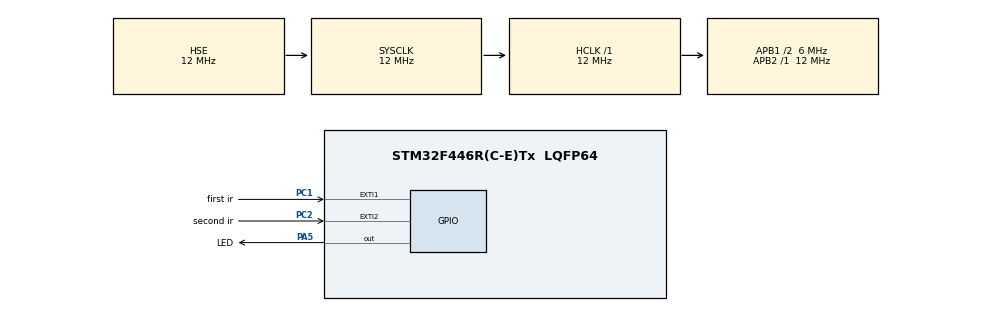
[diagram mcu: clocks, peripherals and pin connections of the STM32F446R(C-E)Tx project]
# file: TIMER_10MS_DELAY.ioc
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Mcu.Family=STM32F4
Mcu.Name=STM32F446R(C-E)Tx
Mcu.Package=LQFP64
NVIC.EXTI1_IRQn=true\:0\:0\:false\:false\:true\:true\:true
NVIC.EXTI2_IRQn=true\:0\:0\:false\:false\:true\:true\:true
NVIC.PriorityGroup=NVIC_PRIORITYGROUP_4
NVIC.TIM6_DAC_IRQn=true\:0\:0\:false\:false\:true\:true\:true
PA5.GPIO_Label=LED
PA5.Signal=GPIO_Output
PC1.GPIO_Label=first ir
PC1.GPIO_ModeDefaultEXTI=GPIO_MODE_IT_RISING
PC1.GPIO_PuPd=GPIO_PULLDOWN
PC1.Signal=GPXTI1
PC2.GPIO_Label=second ir
PC2.GPIO_ModeDefaultEXTI=GPIO_MODE_IT_RISING
PC2.GPIO_PuPd=GPIO_PULLDOWN
PC2.Signal=GPXTI2
PH0-OSC_IN.Mode=HSE-External-Oscillator
PH0-OSC_IN.Signal=RCC_OSC_IN
PH1-OSC_OUT.Mode=HSE-External-Oscillator
PH1-OSC_OUT.Signal=RCC_OSC_OUT
ProjectManager.HeapSize=0x200
ProjectManager.StackSize=0x400
ProjectManager.TargetToolchain=SW4STM32
RCC.AHBFreq_Value=12000000
RCC.APB1CLKDivider=RCC_HCLK_DIV2
RCC.APB1Freq_Value=6000000
RCC.APB1TimFreq_Value=12000000
RCC.APB2Freq_Value=12000000
RCC.APB2TimFreq_Value=12000000
RCC.CortexFreq_Value=12000000
RCC.HCLKFreq_Value=12000000
RCC.HSE_VALUE=12000000
RCC.PLLM=4
RCC.PLLN=50
RCC.PLLSourceVirtual=RCC_PLLSOURCE_HSE
RCC.SYSCLKFreq_VALUE=12000000
RCC.SYSCLKSource=RCC_SYSCLKSOURCE_HSE
RCC.USBFreq_Value=75000000
RCC.VCOOutputFreq_Value=150000000
TIM6.AutoReloadPreload=TIM_AUTORELOAD_PRELOAD_ENABLE
TIM6.Period=120
TIM6.Prescaler=1000
VP_TIM6_VS_ClockSourceINT.Mode=Enable_Timer
board=custom

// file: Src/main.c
/* USER CODE BEGIN Header */
/**
  ******************************************************************************
  * @file           : main.c
  * @brief          : Main program body
  ******************************************************************************
  * @attention
  *
  * <h2><center>&copy; Copyright (c) 2021 STMicroelectronics.
  * All rights reserved.</center></h2>
  *
  * This software component is licensed by ST under BSD 3-Clause license,
  * the "License"; You may not use this file except in compliance with the
  * License. You may obtain a copy of the License at:
  *                        opensource.org/licenses/BSD-3-Clause
  *
  ******************************************************************************
  */
/* USER CODE END Header */

#include "main.h"

TIM_HandleTypeDef htim6;

/* USER CODE BEGIN PV */
float ticks=0.00;
double volume=0.00;
unsigned long overflow=0;
double flow=0.00;		   //for flow calculation flow=vol*60/sec
char flowres[20]={0};
char ticksres[20]={0};
unsigned int countervalue=0;

/* USER CODE END PV */

void SystemClock_Config(void);
static void MX_GPIO_Init(void);
static void MX_TIM6_Init(void);

int main(void)
{
  /* USER CODE BEGIN 1 */
  float id=1.82;   //DIAMETER=3.64 SO ID=DIA/2
  int height=47;
  double pie=3.14159265358; //pie value used for volume calculation

  volume=((pie*(id)*(id)*height)/1000)*60;

  /* USER CODE END 1 */

  /* MCU Configuration--------------------------------------------------------*/

  /* Reset of all peripherals, Initializes the Flash interface and the Systick. */
  HAL_Init();

  /* Configure the system clock */
  SystemClock_Config();

  /* Initialize all configured peripherals */
  MX_GPIO_Init();
  MX_TIM6_Init();
//  HAL_TIM_Base_Start_IT(&htim6);
  /* USER CODE BEGIN 2 */
  HAL_NVIC_DisableIRQ(EXTI2_IRQn); //disable second interrupt in our case it is ir2

  /* USER CODE END 2 */

  /* Infinite loop */
  while (1)
  {

  }
}

void SystemClock_Config(void)
{
  RCC_OscInitTypeDef RCC_OscInitStruct = {0};
  RCC_ClkInitTypeDef RCC_ClkInitStruct = {0};

  /** Configure the main internal regulator output voltage
  */
  __HAL_RCC_PWR_CLK_ENABLE();
  __HAL_PWR_VOLTAGESCALING_CONFIG(PWR_REGULATOR_VOLTAGE_SCALE3);
  /** Initializes the CPU, AHB and APB busses clocks
  */
  RCC_OscInitStruct.OscillatorType = RCC_OSCILLATORTYPE_HSE;
  RCC_OscInitStruct.HSEState = RCC_HSE_ON;
  RCC_OscInitStruct.PLL.PLLState = RCC_PLL_NONE;
  if (HAL_RCC_OscConfig(&RCC_OscInitStruct) != HAL_OK)
  {
    Error_Handler();
  }
  /** Initializes the CPU, AHB and APB busses clocks
  */
  RCC_ClkInitStruct.ClockType = RCC_CLOCKTYPE_HCLK|RCC_CLOCKTYPE_SYSCLK
                              |RCC_CLOCKTYPE_PCLK1|RCC_CLOCKTYPE_PCLK2;
  RCC_ClkInitStruct.SYSCLKSource = RCC_SYSCLKSOURCE_HSE;
  RCC_ClkInitStruct.AHBCLKDivider = RCC_SYSCLK_DIV1;
  RCC_ClkInitStruct.APB1CLKDivider = RCC_HCLK_DIV2;
  RCC_ClkInitStruct.APB2CLKDivider = RCC_HCLK_DIV1;

  if (HAL_RCC_ClockConfig(&RCC_ClkInitStruct, FLASH_LATENCY_0) != HAL_OK)
  {
    Error_Handler();
  }
}

static void MX_TIM6_Init(void)
{

  TIM_MasterConfigTypeDef sMasterConfig = {0};

  htim6.Instance = TIM6;
 // htim6.Init.Prescaler = 1000;      //USING 12MHZ CLOCK SPEED(can be set to one)
  htim6.Init.Prescaler = 1;
  htim6.Init.CounterMode = TIM_COUNTERMODE_UP;
 // htim6.Init.Period = 12000;    //1s delay
  htim6.Init.Period = 65536-1;
  htim6.Init.AutoReloadPreload = TIM_AUTORELOAD_PRELOAD_ENABLE;
  if (HAL_TIM_Base_Init(&htim6) != HAL_OK)
  {
    Error_Handler();
  }
  sMasterConfig.MasterOutputTrigger = TIM_TRGO_RESET;
  sMasterConfig.MasterSlaveMode = TIM_MASTERSLAVEMODE_DISABLE;
  if (HAL_TIMEx_MasterConfigSynchronization(&htim6, &sMasterConfig) != HAL_OK)
  {
    Error_Handler();
  }

}

static void MX_GPIO_Init(void)
{
  GPIO_InitTypeDef GPIO_InitStruct = {0};

  /* GPIO Ports Clock Enable */
  __HAL_RCC_GPIOH_CLK_ENABLE();
  __HAL_RCC_GPIOC_CLK_ENABLE();
  __HAL_RCC_GPIOA_CLK_ENABLE();

  /*Configure GPIO pin Output Level */
  HAL_GPIO_WritePin(LED_GPIO_Port, LED_Pin, GPIO_PIN_RESET);

  /*Configure GPIO pins : first_ir_Pin second_ir_Pin */
  GPIO_InitStruct.Pin = first_ir_Pin|second_ir_Pin;
  GPIO_InitStruct.Mode = GPIO_MODE_IT_RISING;
  GPIO_InitStruct.Pull = GPIO_PULLDOWN;
  HAL_GPIO_Init(GPIOC, &GPIO_InitStruct);

  /*Configure GPIO pin : LED_Pin */
  GPIO_InitStruct.Pin = LED_Pin;
  GPIO_InitStruct.Mode = GPIO_MODE_OUTPUT_PP;
  GPIO_InitStruct.Pull = GPIO_NOPULL;
  GPIO_InitStruct.Speed = GPIO_SPEED_FREQ_LOW;
  HAL_GPIO_Init(LED_GPIO_Port, &GPIO_InitStruct);

  /* EXTI interrupt init*/
  HAL_NVIC_SetPriority(EXTI1_IRQn, 0, 0);
  HAL_NVIC_EnableIRQ(EXTI1_IRQn);

  HAL_NVIC_SetPriority(EXTI2_IRQn, 0, 0);
  HAL_NVIC_EnableIRQ(EXTI2_IRQn);

}

void Error_Handler(void)
{
}

void HAL_GPIO_EXTI_Callback(uint16_t GPIO_Pin)
{
	if(GPIO_Pin == GPIO_PIN_1)
	{
		HAL_TIM_Base_Start_IT(&htim6); //START TIMER IN INTERRUPT MODE
		HAL_NVIC_EnableIRQ(EXTI2_IRQn);    //enable the second interrupt
		HAL_NVIC_DisableIRQ(EXTI1_IRQn);   //disable first interrupt so as to not detect bubble again
	}

	else if(GPIO_Pin == GPIO_PIN_2)
	{
		//SAVE OVERFLOW AND COUNTER REGISTER VALUE
		//TIME CALCULATION
		countervalue=__HAL_TIM_GET_COUNTER(&htim6);   //counter value of timer used for time calculation
		HAL_TIM_Base_Stop_IT(&htim6);
		HAL_NVIC_DisableIRQ(EXTI2_IRQn);
	}

}

/*TIMER CALLBACK FOR LED TOOGLE*/

void HAL_TIM_PeriodElapsedCallback(TIM_HandleTypeDef *htim)
{
	overflow++;
	HAL_GPIO_TogglePin(GPIOA,GPIO_PIN_5);
}

/************************ (C) COPYRIGHT STMicroelectronics *****END OF FILE****/
